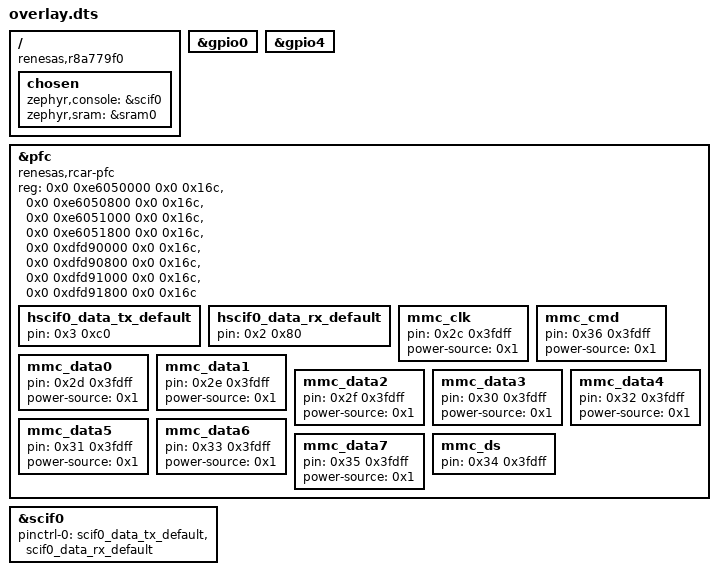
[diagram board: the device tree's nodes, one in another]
/ {
	compatible = "renesas,r8a779f0";
	chosen {
		zephyr,console = &scif0;
		zephyr,sram = &sram0;
	};
};
&gpio0{
	status = "okay";
};
&gpio4{
	status = "okay";
};
&pfc{
	reg = < 0x0 0xe6050000 0x0 0x16c >, < 0x0 0xe6050800 0x0 0x16c >, < 0x0 0xe6051000 0x0 0x16c >, < 0x0 0xe6051800 0x0 0x16c >, < 0x0 0xdfd90000 0x0 0x16c >, < 0x0 0xdfd90800 0x0 0x16c >, < 0x0 0xdfd91000 0x0 0x16c >, < 0x0 0xdfd91800 0x0 0x16c >;
};
&scif0{
	status = "okay";
	pinctrl-0 = < &scif0_data_tx_default &scif0_data_rx_default >;
	pinctrl-names = "default";
};
&pfc{
	compatible = "renesas,rcar-pfc";
	reg = < 0x0 0xe6050000 0x0 0x16c >, < 0x0 0xe6050800 0x0 0x16c >, < 0x0 0xe6051000 0x0 0x16c >, < 0x0 0xe6051800 0x0 0x16c >, < 0x0 0xdfd90000 0x0 0x16c >, < 0x0 0xdfd90800 0x0 0x16c >, < 0x0 0xdfd91000 0x0 0x16c >, < 0x0 0xdfd91800 0x0 0x16c >;
	hscif0_data_tx_default: hscif0_data_tx_default {
		pin = < 0x3 0xc0 >;
	};
	hscif0_data_rx_default: hscif0_data_rx_default {
		pin = < 0x2 0x80 >;
	};
	mmc_clk: mmc_clk {
		pin = < 0x2c 0x3fdff >;
		power-source = < 0x1 >;
	};
	mmc_cmd: mmc_cmd {
		pin = < 0x36 0x3fdff >;
		power-source = < 0x1 >;
	};
	mmc_data0: mmc_data0 {
		pin = < 0x2d 0x3fdff >;
		power-source = < 0x1 >;
	};
	mmc_data1: mmc_data1 {
		pin = < 0x2e 0x3fdff >;
		power-source = < 0x1 >;
	};
	mmc_data2: mmc_data2 {
		pin = < 0x2f 0x3fdff >;
		power-source = < 0x1 >;
	};
	mmc_data3: mmc_data3 {
		pin = < 0x30 0x3fdff >;
		power-source = < 0x1 >;
	};
	mmc_data4: mmc_data4 {
		pin = < 0x32 0x3fdff >;
		power-source = < 0x1 >;
	};
	mmc_data5: mmc_data5 {
		pin = < 0x31 0x3fdff >;
		power-source = < 0x1 >;
	};
	mmc_data6: mmc_data6 {
		pin = < 0x33 0x3fdff >;
		power-source = < 0x1 >;
	};
	mmc_data7: mmc_data7 {
		pin = < 0x35 0x3fdff >;
		power-source = < 0x1 >;
	};
	mmc_ds: mmc_ds {
		pin = < 0x34 0x3fdff >;
	};
};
